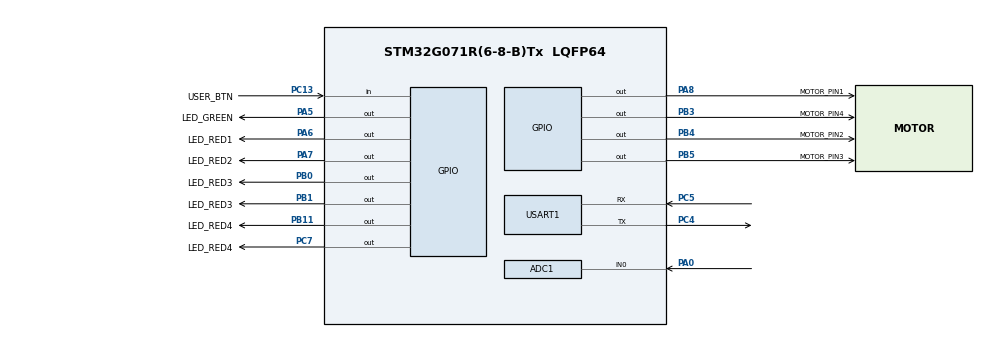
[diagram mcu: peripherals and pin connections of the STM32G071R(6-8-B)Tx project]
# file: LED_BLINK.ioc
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ADC1.Channel-0\#ChannelRegularConversion=ADC_CHANNEL_0
ADC1.ContinuousConvMode=DISABLE
ADC1.DiscontinuousConvMode=ENABLE
ADC1.NbrOfConversionFlag=1
ADC1.Rank-0\#ChannelRegularConversion=1
ADC1.SamplingTime-0\#ChannelRegularConversion=ADC_SAMPLINGTIME_COMMON_1
ADC1.SelectedChannel=ADC_CHANNEL_0
ADC1.master=1
Mcu.Family=STM32G0
Mcu.Name=STM32G071R(6-8-B)Tx
Mcu.Package=LQFP64
NVIC.USART1_IRQn=true\:0\:0\:false\:false\:true\:true\:true\:true
PA0.Mode=IN0
PA0.Signal=ADC1_IN0
PA13.GPIO_Label=TMS
PA13.Mode=Serial_Wire
PA13.Signal=SYS_SWDIO
PA14-BOOT0.GPIO_Label=TCK
PA14-BOOT0.Mode=Serial_Wire
PA14-BOOT0.Signal=SYS_SWCLK
PA5.GPIO_Label=LED_GREEN
PA5.GPIO_Speed=GPIO_SPEED_FREQ_HIGH
PA5.Signal=GPIO_Output
PA6.GPIO_Label=LED_RED1
PA6.Signal=GPIO_Output
PA7.GPIO_Label=LED_RED2
PA7.Signal=GPIO_Output
PA8.GPIO_Label=MOTOR_PIN1
PA8.Signal=GPIO_Output
PB0.GPIO_Label=LED_RED3
PB0.Signal=GPIO_Output
PB1.GPIO_Label=LED_RED3
PB1.Signal=GPIO_Output
PB11.GPIO_Label=LED_RED4
PB11.Signal=GPIO_Output
PB3.GPIO_Label=MOTOR_PIN4
PB3.Signal=GPIO_Output
PB4.GPIO_Label=MOTOR_PIN2
PB4.Signal=GPIO_Output
PB5.GPIO_Label=MOTOR_PIN3
PB5.Signal=GPIO_Output
PC13.GPIO_Label=USER_BTN
PC13.GPIO_PuPd=GPIO_NOPULL
PC13.Signal=GPIO_Input
PC4.Mode=Asynchronous
PC4.Signal=USART1_TX
PC5.Mode=Asynchronous
PC5.Signal=USART1_RX
PC7.GPIO_Label=LED_RED4
PC7.Signal=GPIO_Output
PF0-OSC_IN\ (PF0).GPIO_Label=MCO
PF0-OSC_IN\ (PF0).Mode=HSE-External-Oscillator
PF0-OSC_IN\ (PF0).Signal=RCC_OSC_IN
PF1-OSC_OUT\ (PF1).Mode=HSE-External-Oscillator
PF1-OSC_OUT\ (PF1).Signal=RCC_OSC_OUT
ProjectManager.HeapSize=0x200
ProjectManager.StackSize=0x400
ProjectManager.TargetToolchain=STM32CubeIDE
RCC.ADCFreq_Value=64000000
RCC.AHBFreq_Value=64000000
RCC.CortexFreq_Value=64000000
RCC.EXTERNAL_CLOCK_VALUE=12288000
RCC.HCLKFreq_Value=64000000
RCC.HSE_VALUE=8000000
RCC.HSI_VALUE=16000000
RCC.LSE_VALUE=32768
RCC.SYSCLKFreq_VALUE=64000000
RCC.SYSCLKSource=RCC_SYSCLKSOURCE_PLLCLK
RCC.VCOOutputFreq_Value=128000000
USART1.VirtualMode-Asynchronous=VM_ASYNC
board=NUCLEO-G071RB

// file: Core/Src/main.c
/* USER CODE BEGIN Header */
/**
  ******************************************************************************
  * @file           : main.c
  * @brief          : Main program body
  ******************************************************************************
  * @attention
  *
  * Copyright (c) 2023 STMicroelectronics.
  * All rights reserved.
  *
  * This software is licensed under terms that can be found in the LICENSE file
  * in the root directory of this software component.
  * If no LICENSE file comes with this software, it is provided AS-IS.
  *
  ******************************************************************************
  */
/* USER CODE END Header */
#include "main.h"

/* USER CODE BEGIN Includes */
#include <stdio.h>
#include "EcuM.h"

/* USER CODE END Includes */

void SystemClock_Config(void);
static void MX_GPIO_Init(void);
static void MX_USART1_UART_Init(void);
static void MX_ADC1_Init(void);

int main(void)
{

  /* MCU Configuration--------------------------------------------------------*/

  /* Reset of all peripherals, Initializes the Flash interface and the Systick. */
  LL_APB2_GRP1_EnableClock(LL_APB2_GRP1_PERIPH_SYSCFG);
  LL_APB1_GRP1_EnableClock(LL_APB1_GRP1_PERIPH_PWR);

  /* Configure the system clock */
  SystemClock_Config();

  /* Initialize all configured peripherals */
  MX_GPIO_Init();
  MX_USART1_UART_Init();
  MX_ADC1_Init();
  /* USER CODE BEGIN 2 */
  EcuM_MainFunction();
  /* USER CODE END 2 */

  /* Infinite loop */
  while (1)
  {

  }
}

void SystemClock_Config(void)
{
  LL_FLASH_SetLatency(LL_FLASH_LATENCY_2);
  while(LL_FLASH_GetLatency() != LL_FLASH_LATENCY_2)
  {
  }

  /* HSI configuration and activation */
  LL_RCC_HSI_Enable();
  while(LL_RCC_HSI_IsReady() != 1)
  {
  }

  /* Main PLL configuration and activation */
  LL_RCC_PLL_ConfigDomain_SYS(LL_RCC_PLLSOURCE_HSI, LL_RCC_PLLM_DIV_1, 8, LL_RCC_PLLR_DIV_2);
  LL_RCC_PLL_Enable();
  LL_RCC_PLL_EnableDomain_SYS();
  while(LL_RCC_PLL_IsReady() != 1)
  {
  }

  /* Set AHB prescaler*/
  LL_RCC_SetAHBPrescaler(LL_RCC_SYSCLK_DIV_1);

  /* Sysclk activation on the main PLL */
  LL_RCC_SetSysClkSource(LL_RCC_SYS_CLKSOURCE_PLL);
  while(LL_RCC_GetSysClkSource() != LL_RCC_SYS_CLKSOURCE_STATUS_PLL)
  {
  }

  /* Set APB1 prescaler*/
  LL_RCC_SetAPB1Prescaler(LL_RCC_APB1_DIV_1);
  LL_Init1msTick(64000000);
  /* Update CMSIS variable (which can be updated also through SystemCoreClockUpdate function) */
  LL_SetSystemCoreClock(64000000);
}

static void MX_ADC1_Init(void)
{

  LL_ADC_InitTypeDef ADC_InitStruct = {0};
  LL_ADC_REG_InitTypeDef ADC_REG_InitStruct = {0};

  LL_GPIO_InitTypeDef GPIO_InitStruct = {0};

  /* Peripheral clock enable */
  LL_APB2_GRP1_EnableClock(LL_APB2_GRP1_PERIPH_ADC);

  LL_IOP_GRP1_EnableClock(LL_IOP_GRP1_PERIPH_GPIOA);
  /**ADC1 GPIO Configuration
  PA0   ------> ADC1_IN0
  */
  GPIO_InitStruct.Pin = LL_GPIO_PIN_0;
  GPIO_InitStruct.Mode = LL_GPIO_MODE_ANALOG;
  GPIO_InitStruct.Pull = LL_GPIO_PULL_NO;
  LL_GPIO_Init(GPIOA, &GPIO_InitStruct);

  /** Configure the global features of the ADC (Clock, Resolution, Data Alignment and number of conversion)
  */

   #define ADC_CHANNEL_CONF_RDY_TIMEOUT_MS ( 1U)
   #if (USE_TIMEOUT == 1)
   uint32_t Timeout ; /* Variable used for Timeout management */
   #endif /* USE_TIMEOUT */

  ADC_InitStruct.Clock = LL_ADC_CLOCK_SYNC_PCLK_DIV2;
  ADC_InitStruct.Resolution = LL_ADC_RESOLUTION_12B;
  ADC_InitStruct.DataAlignment = LL_ADC_DATA_ALIGN_RIGHT;
  ADC_InitStruct.LowPowerMode = LL_ADC_LP_MODE_NONE;
  LL_ADC_Init(ADC1, &ADC_InitStruct);
  LL_ADC_REG_SetSequencerConfigurable(ADC1, LL_ADC_REG_SEQ_CONFIGURABLE);

   /* Poll for ADC channel configuration ready */
   #if (USE_TIMEOUT == 1)
   Timeout = ADC_CHANNEL_CONF_RDY_TIMEOUT_MS;
   #endif /* USE_TIMEOUT */
   while (LL_ADC_IsActiveFlag_CCRDY(ADC1) == 0)
     {
   #if (USE_TIMEOUT == 1)
   /* Check Systick counter flag to decrement the time-out value */
   if (LL_SYSTICK_IsActiveCounterFlag())
     {
   if(Timeout-- == 0)
         {
   Error_Handler();
         }
     }
   #endif /* USE_TIMEOUT */
     }
   /* Clear flag ADC channel configuration ready */
   LL_ADC_ClearFlag_CCRDY(ADC1);
  ADC_REG_InitStruct.TriggerSource = LL_ADC_REG_TRIG_SOFTWARE;
  ADC_REG_InitStruct.SequencerLength = LL_ADC_REG_SEQ_SCAN_DISABLE;
  ADC_REG_InitStruct.SequencerDiscont = LL_ADC_REG_SEQ_DISCONT_1RANK;
  ADC_REG_InitStruct.ContinuousMode = LL_ADC_REG_CONV_SINGLE;
  ADC_REG_InitStruct.DMATransfer = LL_ADC_REG_DMA_TRANSFER_NONE;
  ADC_REG_InitStruct.Overrun = LL_ADC_REG_OVR_DATA_PRESERVED;
  LL_ADC_REG_Init(ADC1, &ADC_REG_InitStruct);
  LL_ADC_SetOverSamplingScope(ADC1, LL_ADC_OVS_DISABLE);
  LL_ADC_SetTriggerFrequencyMode(ADC1, LL_ADC_CLOCK_FREQ_MODE_HIGH);
  LL_ADC_SetSamplingTimeCommonChannels(ADC1, LL_ADC_SAMPLINGTIME_COMMON_1, LL_ADC_SAMPLINGTIME_1CYCLE_5);
  LL_ADC_SetSamplingTimeCommonChannels(ADC1, LL_ADC_SAMPLINGTIME_COMMON_2, LL_ADC_SAMPLINGTIME_1CYCLE_5);
  LL_ADC_DisableIT_EOC(ADC1);
  LL_ADC_DisableIT_EOS(ADC1);

   /* Enable ADC internal voltage regulator */
   LL_ADC_EnableInternalRegulator(ADC1);
   /* Delay for ADC internal voltage regulator stabilization. */
   /* Compute number of CPU cycles to wait for, from delay in us. */
   /* Note: Variable divided by 2 to compensate partially */
   /* CPU processing cycles (depends on compilation optimization). */
   /* Note: If system core clock frequency is below 200kHz, wait time */
   /* is only a few CPU processing cycles. */
   uint32_t wait_loop_index;
   wait_loop_index = ((LL_ADC_DELAY_INTERNAL_REGUL_STAB_US * (SystemCoreClock / (100000 * 2))) / 10);
   while(wait_loop_index != 0)
     {
   wait_loop_index--;
     }

  /** Configure Regular Channel
  */
  LL_ADC_REG_SetSequencerRanks(ADC1, LL_ADC_REG_RANK_1, LL_ADC_CHANNEL_0);
  LL_ADC_SetChannelSamplingTime(ADC1, LL_ADC_CHANNEL_0, LL_ADC_SAMPLINGTIME_COMMON_1);

}

static void MX_USART1_UART_Init(void)
{

  LL_USART_InitTypeDef USART_InitStruct = {0};

  LL_GPIO_InitTypeDef GPIO_InitStruct = {0};

  LL_RCC_SetUSARTClockSource(LL_RCC_USART1_CLKSOURCE_PCLK1);

  /* Peripheral clock enable */
  LL_APB2_GRP1_EnableClock(LL_APB2_GRP1_PERIPH_USART1);

  LL_IOP_GRP1_EnableClock(LL_IOP_GRP1_PERIPH_GPIOC);
  /**USART1 GPIO Configuration
  PC4   ------> USART1_TX
  PC5   ------> USART1_RX
  */
  GPIO_InitStruct.Pin = LL_GPIO_PIN_4;
  GPIO_InitStruct.Mode = LL_GPIO_MODE_ALTERNATE;
  GPIO_InitStruct.Speed = LL_GPIO_SPEED_FREQ_LOW;
  GPIO_InitStruct.OutputType = LL_GPIO_OUTPUT_PUSHPULL;
  GPIO_InitStruct.Pull = LL_GPIO_PULL_NO;
  GPIO_InitStruct.Alternate = LL_GPIO_AF_1;
  LL_GPIO_Init(GPIOC, &GPIO_InitStruct);

  GPIO_InitStruct.Pin = LL_GPIO_PIN_5;
  GPIO_InitStruct.Mode = LL_GPIO_MODE_ALTERNATE;
  GPIO_InitStruct.Speed = LL_GPIO_SPEED_FREQ_LOW;
  GPIO_InitStruct.OutputType = LL_GPIO_OUTPUT_PUSHPULL;
  GPIO_InitStruct.Pull = LL_GPIO_PULL_NO;
  GPIO_InitStruct.Alternate = LL_GPIO_AF_1;
  LL_GPIO_Init(GPIOC, &GPIO_InitStruct);

  /* USART1 interrupt Init */
  NVIC_SetPriority(USART1_IRQn, 0);
  NVIC_EnableIRQ(USART1_IRQn);

  USART_InitStruct.PrescalerValue = LL_USART_PRESCALER_DIV1;
  USART_InitStruct.BaudRate = 115200;
  USART_InitStruct.DataWidth = LL_USART_DATAWIDTH_8B;
  USART_InitStruct.StopBits = LL_USART_STOPBITS_1;
  USART_InitStruct.Parity = LL_USART_PARITY_NONE;
  USART_InitStruct.TransferDirection = LL_USART_DIRECTION_TX_RX;
  USART_InitStruct.HardwareFlowControl = LL_USART_HWCONTROL_NONE;
  USART_InitStruct.OverSampling = LL_USART_OVERSAMPLING_16;
  LL_USART_Init(USART1, &USART_InitStruct);
  LL_USART_SetTXFIFOThreshold(USART1, LL_USART_FIFOTHRESHOLD_1_8);
  LL_USART_SetRXFIFOThreshold(USART1, LL_USART_FIFOTHRESHOLD_1_8);
  LL_USART_DisableFIFO(USART1);
  LL_USART_ConfigAsyncMode(USART1);

  LL_USART_Enable(USART1);

  /* Polling USART1 initialisation */
  while((!(LL_USART_IsActiveFlag_TEACK(USART1))) || (!(LL_USART_IsActiveFlag_REACK(USART1))))
  {
  }

}

static void MX_GPIO_Init(void)
{
  LL_GPIO_InitTypeDef GPIO_InitStruct = {0};

  /* GPIO Ports Clock Enable */
  LL_IOP_GRP1_EnableClock(LL_IOP_GRP1_PERIPH_GPIOC);
  LL_IOP_GRP1_EnableClock(LL_IOP_GRP1_PERIPH_GPIOF);
  LL_IOP_GRP1_EnableClock(LL_IOP_GRP1_PERIPH_GPIOA);
  LL_IOP_GRP1_EnableClock(LL_IOP_GRP1_PERIPH_GPIOB);

  /**/
  LL_GPIO_ResetOutputPin(LED_GREEN_GPIO_Port, LED_GREEN_Pin);

  /**/
  LL_GPIO_ResetOutputPin(LED_RED1_GPIO_Port, LED_RED1_Pin);

  /**/
  LL_GPIO_ResetOutputPin(LED_RED2_GPIO_Port, LED_RED2_Pin);

  /**/
  LL_GPIO_ResetOutputPin(LED_RED3_GPIO_Port, LED_RED3_Pin);

  /**/
  LL_GPIO_ResetOutputPin(LED_RED3B1_GPIO_Port, LED_RED3B1_Pin);

  /**/
  LL_GPIO_ResetOutputPin(LED_RED4_GPIO_Port, LED_RED4_Pin);

  /**/
  LL_GPIO_ResetOutputPin(MOTOR_PIN1_GPIO_Port, MOTOR_PIN1_Pin);

  /**/
  LL_GPIO_ResetOutputPin(LED_RED4C7_GPIO_Port, LED_RED4C7_Pin);

  /**/
  LL_GPIO_ResetOutputPin(MOTOR_PIN4_GPIO_Port, MOTOR_PIN4_Pin);

  /**/
  LL_GPIO_ResetOutputPin(MOTOR_PIN2_GPIO_Port, MOTOR_PIN2_Pin);

  /**/
  LL_GPIO_ResetOutputPin(MOTOR_PIN3_GPIO_Port, MOTOR_PIN3_Pin);

  /**/
  GPIO_InitStruct.Pin = USER_BTN_Pin;
  GPIO_InitStruct.Mode = LL_GPIO_MODE_INPUT;
  GPIO_InitStruct.Pull = LL_GPIO_PULL_NO;
  LL_GPIO_Init(USER_BTN_GPIO_Port, &GPIO_InitStruct);

  /**/
  GPIO_InitStruct.Pin = LED_GREEN_Pin;
  GPIO_InitStruct.Mode = LL_GPIO_MODE_OUTPUT;
  GPIO_InitStruct.Speed = LL_GPIO_SPEED_FREQ_HIGH;
  GPIO_InitStruct.OutputType = LL_GPIO_OUTPUT_PUSHPULL;
  GPIO_InitStruct.Pull = LL_GPIO_PULL_NO;
  LL_GPIO_Init(LED_GREEN_GPIO_Port, &GPIO_InitStruct);

  /**/
  GPIO_InitStruct.Pin = LED_RED1_Pin;
  GPIO_InitStruct.Mode = LL_GPIO_MODE_OUTPUT;
  GPIO_InitStruct.Speed = LL_GPIO_SPEED_FREQ_LOW;
  GPIO_InitStruct.OutputType = LL_GPIO_OUTPUT_PUSHPULL;
  GPIO_InitStruct.Pull = LL_GPIO_PULL_NO;
  LL_GPIO_Init(LED_RED1_GPIO_Port, &GPIO_InitStruct);

  /**/
  GPIO_InitStruct.Pin = LED_RED2_Pin;
  GPIO_InitStruct.Mode = LL_GPIO_MODE_OUTPUT;
  GPIO_InitStruct.Speed = LL_GPIO_SPEED_FREQ_LOW;
  GPIO_InitStruct.OutputType = LL_GPIO_OUTPUT_PUSHPULL;
  GPIO_InitStruct.Pull = LL_GPIO_PULL_NO;
  LL_GPIO_Init(LED_RED2_GPIO_Port, &GPIO_InitStruct);

  /**/
  GPIO_InitStruct.Pin = LED_RED3_Pin;
  GPIO_InitStruct.Mode = LL_GPIO_MODE_OUTPUT;
  GPIO_InitStruct.Speed = LL_GPIO_SPEED_FREQ_LOW;
  GPIO_InitStruct.OutputType = LL_GPIO_OUTPUT_PUSHPULL;
  GPIO_InitStruct.Pull = LL_GPIO_PULL_NO;
  LL_GPIO_Init(LED_RED3_GPIO_Port, &GPIO_InitStruct);

  /**/
  GPIO_InitStruct.Pin = LED_RED3B1_Pin;
  GPIO_InitStruct.Mode = LL_GPIO_MODE_OUTPUT;
  GPIO_InitStruct.Speed = LL_GPIO_SPEED_FREQ_LOW;
  GPIO_InitStruct.OutputType = LL_GPIO_OUTPUT_PUSHPULL;
  GPIO_InitStruct.Pull = LL_GPIO_PULL_NO;
  LL_GPIO_Init(LED_RED3B1_GPIO_Port, &GPIO_InitStruct);

  /**/
  GPIO_InitStruct.Pin = LED_RED4_Pin;
  GPIO_InitStruct.Mode = LL_GPIO_MODE_OUTPUT;
  GPIO_InitStruct.Speed = LL_GPIO_SPEED_FREQ_LOW;
  GPIO_InitStruct.OutputType = LL_GPIO_OUTPUT_PUSHPULL;
  GPIO_InitStruct.Pull = LL_GPIO_PULL_NO;
  LL_GPIO_Init(LED_RED4_GPIO_Port, &GPIO_InitStruct);

  /**/
  GPIO_InitStruct.Pin = MOTOR_PIN1_Pin;
  GPIO_InitStruct.Mode = LL_GPIO_MODE_OUTPUT;
  GPIO_InitStruct.Speed = LL_GPIO_SPEED_FREQ_LOW;
  GPIO_InitStruct.OutputType = LL_GPIO_OUTPUT_PUSHPULL;
  GPIO_InitStruct.Pull = LL_GPIO_PULL_NO;
  LL_GPIO_Init(MOTOR_PIN1_GPIO_Port, &GPIO_InitStruct);

  /**/
  GPIO_InitStruct.Pin = LED_RED4C7_Pin;
  GPIO_InitStruct.Mode = LL_GPIO_MODE_OUTPUT;
  GPIO_InitStruct.Speed = LL_GPIO_SPEED_FREQ_LOW;
  GPIO_InitStruct.OutputType = LL_GPIO_OUTPUT_PUSHPULL;
  GPIO_InitStruct.Pull = LL_GPIO_PULL_NO;
  LL_GPIO_Init(LED_RED4C7_GPIO_Port, &GPIO_InitStruct);

  /**/
  GPIO_InitStruct.Pin = MOTOR_PIN4_Pin;
  GPIO_InitStruct.Mode = LL_GPIO_MODE_OUTPUT;
  GPIO_InitStruct.Speed = LL_GPIO_SPEED_FREQ_LOW;
  GPIO_InitStruct.OutputType = LL_GPIO_OUTPUT_PUSHPULL;
  GPIO_InitStruct.Pull = LL_GPIO_PULL_NO;
  LL_GPIO_Init(MOTOR_PIN4_GPIO_Port, &GPIO_InitStruct);

  /**/
  GPIO_InitStruct.Pin = MOTOR_PIN2_Pin;
  GPIO_InitStruct.Mode = LL_GPIO_MODE_OUTPUT;
  GPIO_InitStruct.Speed = LL_GPIO_SPEED_FREQ_LOW;
  GPIO_InitStruct.OutputType = LL_GPIO_OUTPUT_PUSHPULL;
  GPIO_InitStruct.Pull = LL_GPIO_PULL_NO;
  LL_GPIO_Init(MOTOR_PIN2_GPIO_Port, &GPIO_InitStruct);

  /**/
  GPIO_InitStruct.Pin = MOTOR_PIN3_Pin;
  GPIO_InitStruct.Mode = LL_GPIO_MODE_OUTPUT;
  GPIO_InitStruct.Speed = LL_GPIO_SPEED_FREQ_LOW;
  GPIO_InitStruct.OutputType = LL_GPIO_OUTPUT_PUSHPULL;
  GPIO_InitStruct.Pull = LL_GPIO_PULL_NO;
  LL_GPIO_Init(MOTOR_PIN3_GPIO_Port, &GPIO_InitStruct);

}

/* USER CODE BEGIN 4 */

//void usart_transmit_data(const void* data, uint16_t len) {
//    const uint8_t* b = data;
//    while (len--) {
//        LL_USART_TransmitData8(USART1, *b++);
//
//        while (!LL_USART_IsActiveFlag_TXE(USART1)){
////          transmit_empty_register=LL_USART_IsActiveFlag_TXE(USART1);
////          transfer_complete=LL_USART_IsActiveFlag_TC(USART1);
//          //LL_USART_ClearFlag_PE(USART1);
//        }
//     }
//}

//int _write(int file, uint8_t *buf, int nbytes)
//{
//    uint8_t num_of_byte = 0;
//    while(num_of_byte <= nbytes - 1)
//    {
//        //waiting until the Transmit Empty flag is set
//        while(!LL_USART_IsActiveFlag_TXE(USART1));
//        //send data byte by byte
////        SET_BIT(USART1->CR1, USART_CR1_TE);
//        LL_USART_TransmitData8(USART1, buf[num_of_byte++]);
//    }
//    //Wait until the transmit complete Flag to be raised
//    while (!LL_USART_IsActiveFlag_TC(USART1));
//    return nbytes;
//}
/* USER CODE END 4 */

void Error_Handler(void)
{
  __disable_irq();
  while (1)
  {
  }
}
